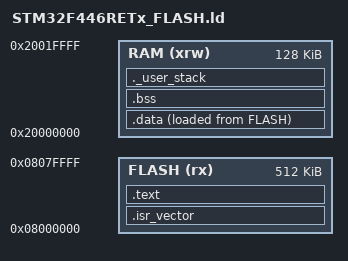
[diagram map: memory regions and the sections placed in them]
/* STM32F446RE — 512 KiB flash, 128 KiB SRAM */
ENTRY(Reset_Handler)

_Min_Stack_Size = 0x2000;

_estack = ORIGIN(RAM) + LENGTH(RAM);

MEMORY
{
  FLASH (rx)  : ORIGIN = 0x08000000, LENGTH = 512K
  RAM (xrw)   : ORIGIN = 0x20000000, LENGTH = 128K
}

SECTIONS
{
  .isr_vector :
  {
    KEEP(*(.isr_vector))
  } > FLASH

  .text :
  {
    *(.text*)
    *(.rodata*)
    KEEP(*(.init))
    KEEP(*(.fini))
    _etext = .;
  } > FLASH

  _sidata = LOADADDR(.data);

  .data :
  {
    _sdata = .;
    *(.data*)
    _edata = .;
  } > RAM AT > FLASH

  .bss :
  {
    _sbss = .;
    *(.bss*)
    *(COMMON)
    _ebss = .;
  } > RAM

  ._user_stack (NOLOAD) :
  {
    . = ALIGN(8);
    . = . + _Min_Stack_Size;
  } > RAM

  . = ALIGN(8);
  _end = .;
  PROVIDE(end = .);
  PROVIDE(_end = .);

  /DISCARD/ :
  {
    *(.ARM.exidx*)
    *(.ARM.extab*)
  }
}
